# GD32E53x register map
File version: 1.0
CPU: CM33 r0p4, little endian, MPU, FPU, 4 interrupt priority bits
Registers are 32-bit, read-write, reset 0x0 unless marked. A register's access mark holds for its fields unless they carry their own. Offsets are from the block's base; [hi:lo] are bit positions; {n}, {i} and the like mark numbered series.

## DBG — Debug
Base 0xE0054000
0x00 ID ro — ID code register
  [31:0] ID_CODE — DBG ID code register
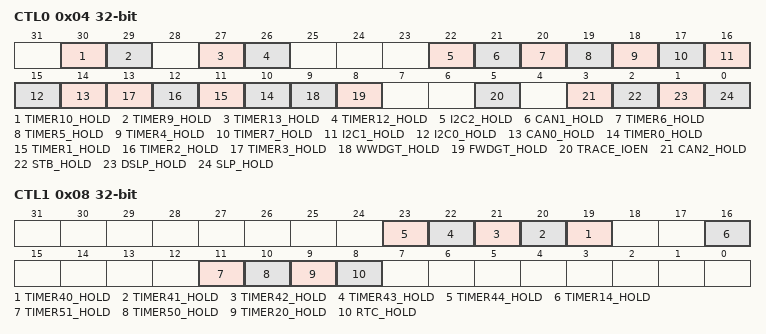
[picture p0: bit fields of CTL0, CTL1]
0x04 CTL0 — Control register0
  [30] TIMER10_HOLD — TIMER10 hold bit
  [29] TIMER9_HOLD — TIMER9 hold bit
  [27] TIMER13_HOLD — TIMER13 hold bit
  [26] TIMER12_HOLD — TIMER12 hold bit
  [22] I2C2_HOLD — I2C2 hold bit
  [21] CAN1_HOLD — CAN1 hold bit
  [20] TIMER6_HOLD — TIMER6 hold bit
  [19] TIMER5_HOLD — TIMER5 hold bit
  [18] TIMER4_HOLD — TIMER4 hold bit
  [17] TIMER7_HOLD — TIMER7 hold bit
  [16] I2C1_HOLD — I2C1 hold bit
  [15] I2C0_HOLD — I2C0 hold bit
  [14] CAN0_HOLD — CAN0 hold bit
  [n+10] TIMER{n}_HOLD (n=0..3) — TIMER{n} hold bit
  [9] WWDGT_HOLD — WWDGT hold bit
  [8] FWDGT_HOLD — FWDGT hold bit
  [5] TRACE_IOEN — Trace pin allocation enable
  [3] CAN2_HOLD — CAN2 hold bit
  [2] STB_HOLD — Standby mode hold register
  [1] DSLP_HOLD — Deep-sleep mode hold register
  [0] SLP_HOLD — Sleep mode hold register
0x08 CTL1 — Control register1
  [n-21] TIMER{n}_HOLD (n=40..44) — TIMER{n} hold bit
  [16] TIMER14_HOLD — TIMER14 hold bit
  [11] TIMER51_HOLD — TIMER51 hold bit
  [10] TIMER50_HOLD — TIMER50 hold bit
  [9] TIMER20_HOLD — TIMER20 hold bit
  [8] RTC_HOLD — RTC hold bit
0x0C CTL2 reset 0x80000000 — Control register2
  [31] LK — DBG register unlock

## DCACHE — Data cache
Base 0x40026400
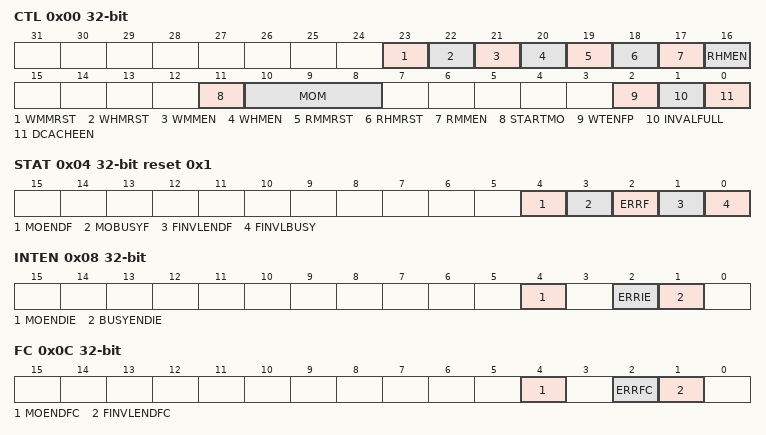
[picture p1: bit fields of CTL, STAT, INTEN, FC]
0x00 CTL access per field — Control register
  [23] WMMRST rw — Write-miss monitor reset
  [22] WHMRST rw — Write-hit monitor reset
  [21] WMMEN rw — Write-miss monitor enable
  [20] WHMEN rw — Write-hit monitor enable
  [19] RMMRST rw — Read-miss monitor reset
  [18] RHMRST rw — Read-Hit monitor reset
  [17] RMMEN rw — Read-miss monitor enable
  [16] RHMEN rw — Read-hit monitor enable
  [11] STARTMO rw — Start cache maintenance operations.
  [10:8] MOM rw — maintenance operations mode
  [2] WTENFP rw — Write-Through with Enforcement policy
  [1] INVALFULL wo — invalidate the full cache
  [0] DCACHEEN rw — Dcache enable
0x04 STAT ro reset 0x1 — Status register
  [4] MOENDF — maintenance operation end flag
  [3] MOBUSYF — maintenance operation busy flag
  [2] ERRF — dcache error flag
  [1] FINVLENDF — full invalidate operation end flag
  [0] FINVLBUSY — full invalidate operation busy flag
0x08 INTEN — Interrupt enable register
  [4] MOENDIE — maintenance operation end interrupt enable
  [2] ERRIE — Cache error interrupt enable
  [1] BUSYENDIE — busy end interrupt enable
0x0C FC wo — Flag clear register
  [4] MOENDFC — Software clear maintenance operation end flag
  [2] ERRFC — Software clear cache error flag
  [1] FINVLENDFC — Software clear full invalidate operation end flag
0x10 RHMC ro — Read-hit monitor counter register
  [31:0] RHMC — Read-hit monitor counter.
0x14 RMMC ro — Read-miss monitor counter register
  [31:0] RMMC — Read-miss monitor counter
0x20 WHMC ro — Write-hit monitor counter register
  [31:0] WHMC — Write-hit monitor counter.
0x24 WMMC ro — Write-miss monitor counter register
  [31:0] WMMC — Write-miss monitor counter
0x28 MOSADDR — Maintenance operation start address register
  [31:4] MOSADDR — Maintenance operation start address
0x2C MOEADDR — Maintenance operation end address register
  [31:4] MOEADDR — Maintenance operation end address

## DMAMUX — DMA request multiplexer
Base 0x40020800
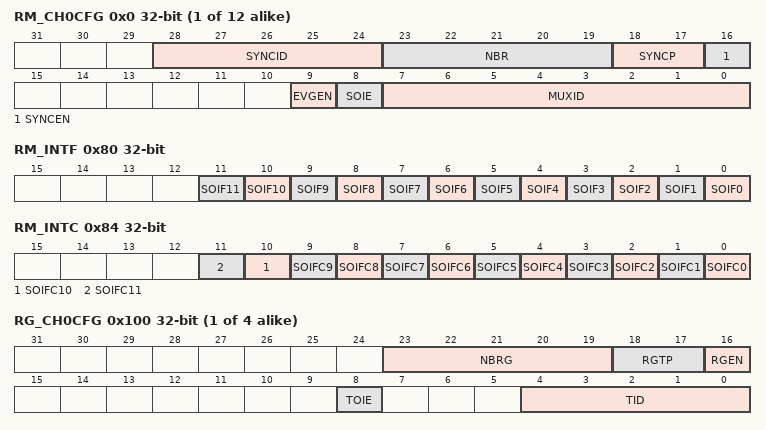
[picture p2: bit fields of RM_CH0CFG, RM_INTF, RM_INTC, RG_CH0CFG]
{0x0+4i} RM_CH{i}CFG (i=0..11) — Request multiplexer channel {i} configuration regist
  [28:24] SYNCID — Synchronization input identification
  [23:19] NBR — Number of DMA requests to forward
  [18:17] SYNCP — Synchronization input polarity
  [16] SYNCEN — Synchronization enable
  [9] EVGEN — Event generation enable
  [8] SOIE — Synchronization overrun interrupt enable
  [7:0] MUXID — Multiplexer input identification
0x80 RM_INTF ro — Request multiplexer channel interrupt flag register
  [n] SOIF{n} (n=0..11) — Synchronization overrun event flag of request multiple11er channel {n}
0x84 RM_INTC wo — Request multiplexer channel interrupt flag clear register
  [n] SOIFC{n} (n=0..11) — Clear bit for synchronization overrun event flag of request multiple11er channel {n}
{0x100+4i} RG_CH{i}CFG (i=0..3) — Request generator channel {i} configuration regist
  [23:19] NBRG — Number of DMA requests to be generated
  [18:17] RGTP — DMA request generator trigger polarity
  [16] RGEN — DMA request generator channel x enable
  [8] TOIE — Trigger overrun interrupt enable
  [4:0] TID — Trigger input identification
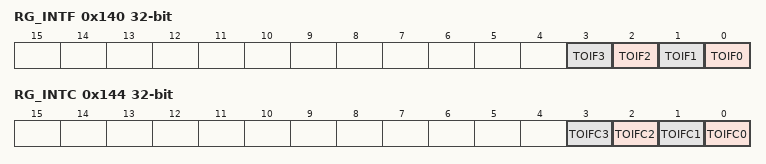
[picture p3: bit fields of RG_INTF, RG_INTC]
0x140 RG_INTF ro — Request generator interrupt flag register
  [n] TOIF{n} (n=0..3) — Trigger overrun event flag of request generator channel {n}
0x144 RG_INTC wo — Request generator interrupt flag clear register
  [n] TOIFC{n} (n=0..3) — Clear bit for trigger overrun event flag of request generator channel {n}
